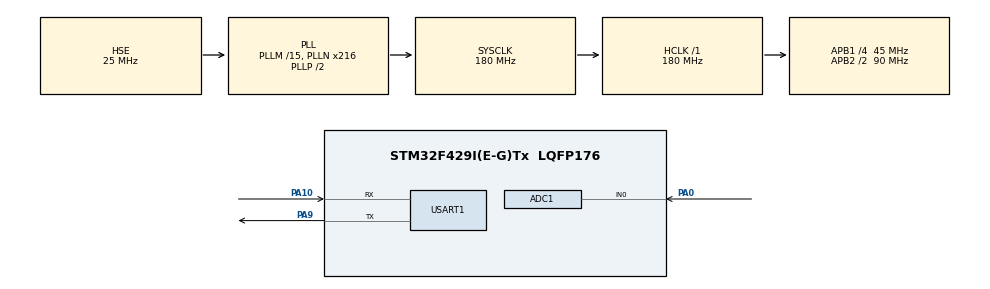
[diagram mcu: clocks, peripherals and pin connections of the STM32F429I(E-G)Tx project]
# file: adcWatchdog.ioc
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ADC1.Channel-0\#ChannelRegularConversion=ADC_CHANNEL_0
ADC1.ContinuousConvMode=ENABLE
ADC1.EnableAnalogWatchDog=true
ADC1.HighThreshold=3000
ADC1.ITMode=ENABLE
ADC1.LowThreshold=1000
ADC1.NbrOfConversion=1
ADC1.NbrOfConversionFlag=1
ADC1.Rank-0\#ChannelRegularConversion=1
ADC1.SamplingTime-0\#ChannelRegularConversion=ADC_SAMPLETIME_84CYCLES
ADC1.master=1
Mcu.Family=STM32F4
Mcu.Name=STM32F429I(E-G)Tx
Mcu.Package=LQFP176
NVIC.ADC_IRQn=true\:0\:0\:false\:false\:true\:true\:true\:true
NVIC.PriorityGroup=NVIC_PRIORITYGROUP_4
PA0/WKUP.Signal=ADCx_IN0
PA10.Mode=Asynchronous
PA10.Signal=USART1_RX
PA13.Mode=Serial_Wire
PA13.Signal=SYS_JTMS-SWDIO
PA14.Mode=Serial_Wire
PA14.Signal=SYS_JTCK-SWCLK
PA9.Mode=Asynchronous
PA9.Signal=USART1_TX
PH0/OSC_IN.Mode=HSE-External-Oscillator
PH0/OSC_IN.Signal=RCC_OSC_IN
PH1/OSC_OUT.Mode=HSE-External-Oscillator
PH1/OSC_OUT.Signal=RCC_OSC_OUT
ProjectManager.HeapSize=0x200
ProjectManager.StackSize=0x400
ProjectManager.TargetToolchain=MDK-ARM V5
RCC.48MHZClocksFreq_Value=90000000
RCC.AHBFreq_Value=180000000
RCC.APB1CLKDivider=RCC_HCLK_DIV4
RCC.APB1Freq_Value=45000000
RCC.APB1TimFreq_Value=90000000
RCC.APB2CLKDivider=RCC_HCLK_DIV2
RCC.APB2Freq_Value=90000000
RCC.APB2TimFreq_Value=180000000
RCC.CortexFreq_Value=180000000
RCC.HCLKFreq_Value=180000000
RCC.HSE_VALUE=25000000
RCC.HSI_VALUE=16000000
RCC.LSE_VALUE=32768
RCC.PLLM=15
RCC.PLLN=216
RCC.PLLSourceVirtual=RCC_PLLSOURCE_HSE
RCC.SYSCLKFreq_VALUE=180000000
RCC.SYSCLKSource=RCC_SYSCLKSOURCE_PLLCLK
RCC.VCOOutputFreq_Value=360000000
SH.ADCx_IN0.0=ADC1_IN0,IN0
USART1.VirtualMode=VM_ASYNC
board=custom

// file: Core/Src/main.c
/* USER CODE BEGIN Header */
/**
  ******************************************************************************
  * @file           : main.c
  * @brief          : Main program body
  ******************************************************************************
  * @attention
  *
  * Copyright (c) 2025 STMicroelectronics.
  * All rights reserved.
  *
  * This software is licensed under terms that can be found in the LICENSE file
  * in the root directory of this software component.
  * If no LICENSE file comes with this software, it is provided AS-IS.
  *
  ******************************************************************************
  */
/* USER CODE END Header */
#include "main.h"
#include "adc.h"
#include "usart.h"
#include "gpio.h"

/* USER CODE BEGIN Includes */
#include "adc_watchdog.h"
#include <stdio.h>
/* USER CODE END Includes */

void SystemClock_Config(void);

/* USER CODE BEGIN 0 */
int fputc(int ch, FILE *f)
{
    HAL_UART_Transmit(&huart1, (uint8_t *)&ch, 1, 10);
    return ch;
}
/* USER CODE END 0 */

int main(void)
{

  /* MCU Configuration--------------------------------------------------------*/

  /* Reset of all peripherals, Initializes the Flash interface and the Systick. */
  HAL_Init();

  /* Configure the system clock */
  SystemClock_Config();

  /* Initialize all configured peripherals */
  MX_GPIO_Init();
  MX_ADC1_Init();
  MX_USART1_UART_Init();
  /* USER CODE BEGIN 2 */
	AWD_Init(&hadc1);

	/* 设置监测范围: 1.0V ~ 2.5V */
	AWD_SetThreshold(1.0f, 2.5f);

	AWD_Status_t status;
	AWD_GetStatus(&status);
	printf("Threshold: %.2fV ~ %.2fV\r\n",
				 status.low_voltage, status.high_voltage);
	printf("Rotate potentiometer to test...\r\n\r\n");

	AWD_Start();
  /* USER CODE END 2 */

  /* Infinite loop */
  while (1)
  {

    /* USER CODE BEGIN 3 */
		/* 检查报警 */
		if (AWD_IsAlarm()) {
				AWD_AlarmType_t type = AWD_GetAlarmType();
				float voltage = AWD_GetCurrentVoltage();

				if (type == AWD_ALARM_HIGH) {
						printf("[ALARM] Over voltage! %.3fV > %.2fV\r\n",
									 voltage, status.high_voltage);
				} else if (type == AWD_ALARM_LOW) {
						printf("[ALARM] Under voltage! %.3fV < %.2fV\r\n",
									 voltage, status.low_voltage);
				}
		}

		/* 定期显示当前电压 */
		static uint32_t last_print = 0;
		if (HAL_GetTick() - last_print > 500) {
				last_print = HAL_GetTick();

				printf("Current: %.3fV (count=%d)\r\n",
							 AWD_GetCurrentVoltage(),
							 status.alarm_count);

				AWD_GetStatus(&status);
		}
  }
  /* USER CODE END 3 */
}

void SystemClock_Config(void)
{
  RCC_OscInitTypeDef RCC_OscInitStruct = {0};
  RCC_ClkInitTypeDef RCC_ClkInitStruct = {0};

  /** Configure the main internal regulator output voltage
  */
  __HAL_RCC_PWR_CLK_ENABLE();
  __HAL_PWR_VOLTAGESCALING_CONFIG(PWR_REGULATOR_VOLTAGE_SCALE1);

  /** Initializes the RCC Oscillators according to the specified parameters
  * in the RCC_OscInitTypeDef structure.
  */
  RCC_OscInitStruct.OscillatorType = RCC_OSCILLATORTYPE_HSE;
  RCC_OscInitStruct.HSEState = RCC_HSE_ON;
  RCC_OscInitStruct.PLL.PLLState = RCC_PLL_ON;
  RCC_OscInitStruct.PLL.PLLSource = RCC_PLLSOURCE_HSE;
  RCC_OscInitStruct.PLL.PLLM = 15;
  RCC_OscInitStruct.PLL.PLLN = 216;
  RCC_OscInitStruct.PLL.PLLP = RCC_PLLP_DIV2;
  RCC_OscInitStruct.PLL.PLLQ = 4;
  if (HAL_RCC_OscConfig(&RCC_OscInitStruct) != HAL_OK)
  {
    Error_Handler();
  }

  /** Activate the Over-Drive mode
  */
  if (HAL_PWREx_EnableOverDrive() != HAL_OK)
  {
    Error_Handler();
  }

  /** Initializes the CPU, AHB and APB buses clocks
  */
  RCC_ClkInitStruct.ClockType = RCC_CLOCKTYPE_HCLK|RCC_CLOCKTYPE_SYSCLK
                              |RCC_CLOCKTYPE_PCLK1|RCC_CLOCKTYPE_PCLK2;
  RCC_ClkInitStruct.SYSCLKSource = RCC_SYSCLKSOURCE_PLLCLK;
  RCC_ClkInitStruct.AHBCLKDivider = RCC_SYSCLK_DIV1;
  RCC_ClkInitStruct.APB1CLKDivider = RCC_HCLK_DIV4;
  RCC_ClkInitStruct.APB2CLKDivider = RCC_HCLK_DIV2;

  if (HAL_RCC_ClockConfig(&RCC_ClkInitStruct, FLASH_LATENCY_5) != HAL_OK)
  {
    Error_Handler();
  }
}

void Error_Handler(void)
{
  __disable_irq();
  while (1)
  {
  }
}
